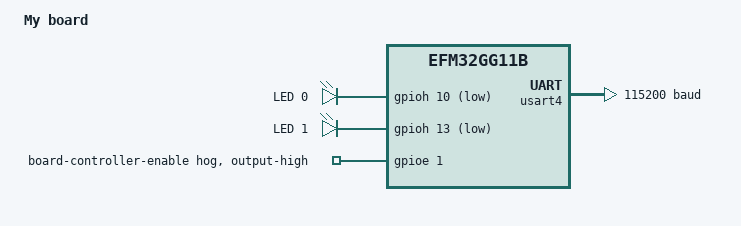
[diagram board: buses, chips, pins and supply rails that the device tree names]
/dts-v1/;

#include <silabs/efm32gg11b820f2048gl192.dtsi>
#include "my_board-pinctrl.dtsi"

/ {
	model = "My board";
	compatible = "my_vendor,my_board", "silabs,efm32gg11b";

	aliases
	{
		led0 = &led0;
		led1 = &led1;
	};

	chosen
	{
		zephyr,console = &usart4;
		zephyr,flash = &flash0;
		zephyr,shell-uart = &usart4;
		zephyr,sram = &sram0;
	};

	leds {
		compatible = "gpio-leds";

		led0: led_0 {
			gpios = <&gpioh 10 GPIO_ACTIVE_LOW>;
			label = "LED 0";
		};

		led1: led_1 {
			gpios = <&gpioh 13 GPIO_ACTIVE_LOW>;
			label = "LED 1";
		};
	};
};

&usart4 {
	current-speed = <115200>;
	pinctrl-0 = <&usart4_default>;
	pinctrl-names = "default";
	status = "okay";
};

&gpioe {
	status = "okay";

	board-controller-enable {
		gpio-hog;
		gpios = <1 GPIO_ACTIVE_HIGH>;
		output-high;
	};
};

&gpioh {
	status = "okay";
};

&flash0 {
	partitions {
		compatible = "fixed-partitions";
		#address-cells = <1>;
		#size-cells = <1>;

		/* Set 12Kb of storage at the end of the 2048Kb of flash */
		storage_partition: partition@1fd000 {
			reg = <0x001fd000 0x00003000>;
			label = "storage";
		};
	};
};

&cpu0 {
	clock-frequency = <72000000>;
};
